# GD32E53x register map
File version: 1.0
CPU: CM33 r0p4, little endian, MPU, FPU, 4 interrupt priority bits
Registers are 32-bit, read-write, reset 0x0 unless marked. A register's access mark holds for its fields unless they carry their own. Offsets are from the block's base; [hi:lo] are bit positions; {n}, {i} and the like mark numbered series; 'fields as' and 'values as' point back to an identical list.

## SYSCFG — System and memory architectur
Base 0x40019800
0x00 CFG0 ro — Configuration register 0
  [2:0] BOOT_MODE
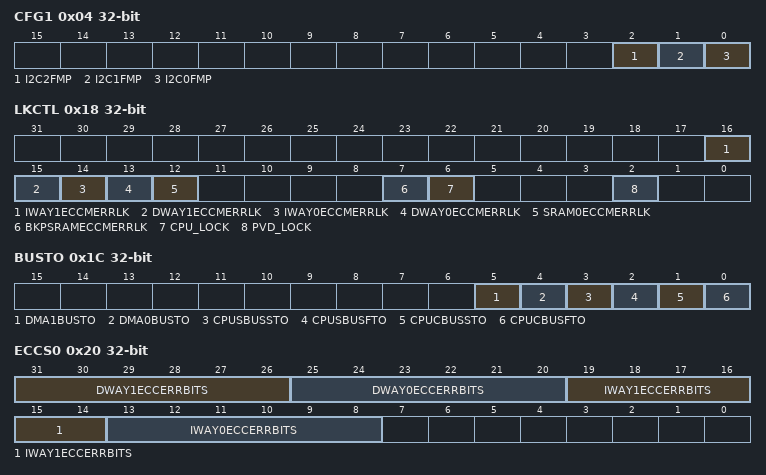
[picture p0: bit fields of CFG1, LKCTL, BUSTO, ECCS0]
0x04 CFG1 — Configuration register 1
  [2] I2C2FMP — I2C2 Fm+
  [1] I2C1FMP — I2C1 Fm+
  [0] I2C0FMP — I2C0 Fm+
0x18 LKCTL — Lockup control register
  [16] IWAY1ECCMERRLK — ICACHE way1 SRAM ECC multi-bits non-correction error lock bit
  [15] DWAY1ECCMERRLK — DCACHE way1 SRAM ECC multi-bits non-correction error lock bit
  [14] IWAY0ECCMERRLK — ICACHE way0 SRAM ECC multi-bits non-correction error lock bit
  [13] DWAY0ECCMERRLK — DCACHE way0 SRAM ECC multi-bits non-correction error lock bit
  [12] SRAM0ECCMERRLK — SRAM0 ECC multi-bits non-correction error lockup bit
  [7] BKPSRAMECCMERRLK — BKPSRAM ECC multi-bits non-correction lockup bit
  [6] CPU_LOCK — CPU lockup bit
  [2] PVD_LOCK — Programmable voltage detector lockup bit.
0x1C BUSTO — Bus timeout register
  [5] DMA1BUSTO — DMA1 bus timeout enable bit.
  [4] DMA0BUSTO — DMA0 bus timeout enable bit.
  [3] CPUSBUSSTO — CPU Sbus-Slow timeout enable bit.
  [2] CPUSBUSFTO — CPU Sbus-Fast timeout enable bit.
  [1] CPUCBUSSTO — CPU Cbus-Slow timeout enable bit.
  [0] CPUCBUSFTO — CPU Cbus-Fast timeout enable bit.
0x20 ECCS0 ro — SRAM_ECC error status register 0
  [31:26] DWAY1ECCERRBITS — Indicates the error bit of the DCACHE way1
  [25:20] DWAY0ECCERRBITS — Indicates the error bit of the DCACHE way0
  [19:14] IWAY1ECCERRBITS — Indicates the error bit of the ICACHE way1
  [13:8] IWAY0ECCERRBITS — Indicates the error bit of the ICACHE way0
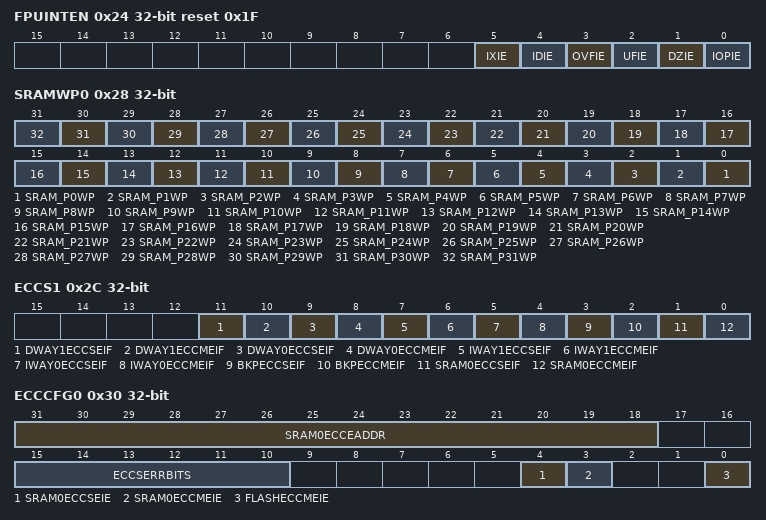
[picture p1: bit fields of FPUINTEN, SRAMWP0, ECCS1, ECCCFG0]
0x24 FPUINTEN reset 0x1F — FPU interrupt enable register
  [5] IXIE — Inexact interrupt enable bit
  [4] IDIE — Input denormal interrupt enable bit
  [3] OVFIE — Overflow interrupt enable bit
  [2] UFIE — Underflow interrupt enable bit
  [1] DZIE — Divide by 0 interrupt enable bit
  [0] IOPIE — Invalid operation interrupt enable bit
0x28 SRAMWP0 — SRAM write protection register0
  [n] SRAM_P{n}WP (n=0..31) — SRAM page {n} write protection
0x2C ECCS1 — SRAM ECC error status register 1
  [11] DWAY1ECCSEIF — DCACHE way1 SRAM single-bit correction event flag
  [10] DWAY1ECCMEIF — DCACHE way1 SRAM multi-bits non-correction error flag
  [9] DWAY0ECCSEIF — DCACHE way0 SRAM single-bit correction event flag
  [8] DWAY0ECCMEIF — DCACHE way0 SRAM multi-bits non-correction error flag
  [7] IWAY1ECCSEIF — ICACHE way1 SRAM single-bit correction event flag
  [6] IWAY1ECCMEIF — ICACHE way1 SRAM multi-bits non-correction error flag
  [5] IWAY0ECCSEIF — ICACHE way0 SRAM single-bit correction event flag
  [4] IWAY0ECCMEIF — ICACHE way0 SRAM multi-bits non-correction error flag
  [3] BKPECCSEIF — BKPSRAM single-bit correction event flag
  [2] BKPECCMEIF — BKPSRAM multi-bits non-correction error flag
  [1] SRAM0ECCSEIF — SRAM0 single bit correction error flag
  [0] SRAM0ECCMEIF — SRAM0 multi-bits non-correction error flag
0x30 ECCCFG0 access per field — ECC configuration register
  [31:18] SRAM0ECCEADDR ro — Record the faulting system address where the last SRAM ECC event on SRAM0 occurred.
  [15:10] ECCSERRBITS ro — Indicates the error bit
  [4] SRAM0ECCSEIE rw — SRAM0 single bit correction error NMI interrupt enable
  [3] SRAM0ECCMEIE rw — SRAM0 multi-bits non-correction error NMI interrupt enable
  [0] FLASHECCMEIE rw — Flash multi-bits non-correction error NMI interrupt enable
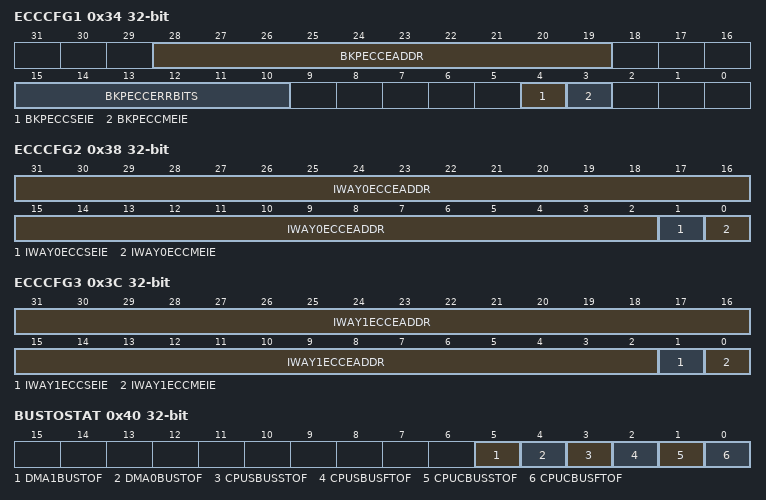
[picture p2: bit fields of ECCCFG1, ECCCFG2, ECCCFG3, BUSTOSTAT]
0x34 ECCCFG1 access per field — SRAM ECC configuration register
  [28:19] BKPECCEADDR ro — Indicates the last ECC event onBKPSRAM occurred.
  [15:10] BKPECCERRBITS ro — Indicates the error bit of the BKPSRAM
  [4] BKPECCSEIE rw — BKPSRAM single bit correction error interrupt enable
  [3] BKPECCMEIE rw — BKPSRAM multi-bits non-correction error NMI interrupt enable
0x38 ECCCFG2 access per field — SRAM ECC configuration register
  [31:2] IWAY0ECCEADDR ro — Indicates the last ECC event on ICACHE way0 SRAM occurred.
  [1] IWAY0ECCSEIE rw — ICACHE way0 single bit correction error interrupt enable
  [0] IWAY0ECCMEIE rw — ICACHE way0 multi-bits non-correction error NMI interrupt enable
0x3C ECCCFG3 access per field — SRAM ECC configuration register
  [31:2] IWAY1ECCEADDR ro — Indicates the last ECC event on ICACHE way1 SRAM occurred.
  [1] IWAY1ECCSEIE rw — ICACHE way1 single bit correction error NMI interrupt enable
  [0] IWAY1ECCMEIE rw — ICACHE way0 multi-bits (two bits) non-correction error NMI interrupt enable
0x40 BUSTOSTAT — Bus timeout states register
  [5] DMA1BUSTOF — DMA1 bus timeout flag.
  [4] DMA0BUSTOF — DMA0 bus timeout flag.
  [3] CPUSBUSSTOF — CPU Sbus-Slow timeout flag.
  [2] CPUSBUSFTOF — CPU Sbus-Fast timeout flag.
  [1] CPUCBUSSTOF — CPU Cbus-Slow timeout flag.
  [0] CPUCBUSFTOF — CPU Cbus-Fast timeout flag.
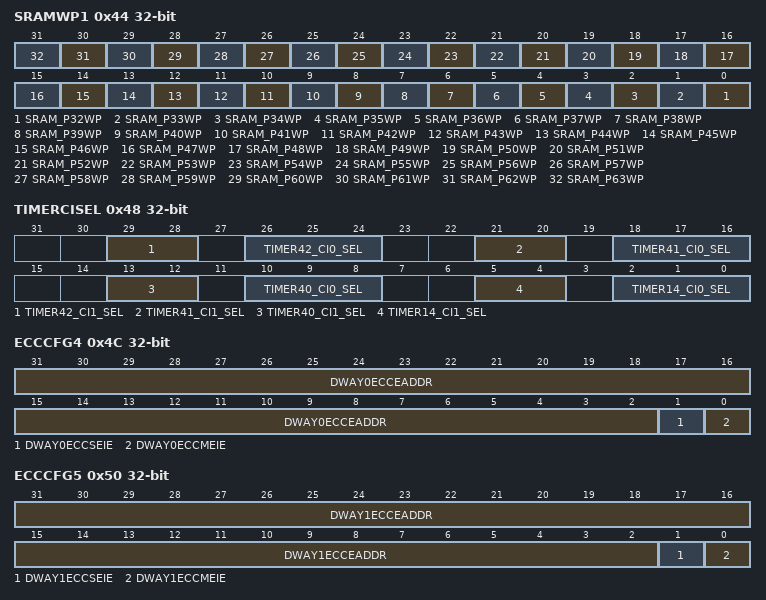
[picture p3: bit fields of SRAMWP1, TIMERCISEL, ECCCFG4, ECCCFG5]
0x44 SRAMWP1 — SRAM write protection register1
  [n-32] SRAM_P{n}WP (n=32..63) — SRAM page {n} write protection
0x48 TIMERCISEL — Timer input selection register
  [29:28] TIMER42_CI1_SEL — Selects TIMER42_CI1 input
  [26:24] TIMER42_CI0_SEL — Selects TIMER42_CI0 input
  [21:20] TIMER41_CI1_SEL — Selects TIMER41_CI1 input
  [18:16] TIMER41_CI0_SEL — Selects TIMER41_CI0 input
  [13:12] TIMER40_CI1_SEL — Selects TIMER40_CI1 input
  [10:8] TIMER40_CI0_SEL — Selects TIMER40_CI0 input
  [5:4] TIMER14_CI1_SEL — Selects TIMER14_CI1 input
  [2:0] TIMER14_CI0_SEL — Selects TIMER14_CI0 input
0x4C ECCCFG4 access per field — SRAM ECC configuration register
  [31:2] DWAY0ECCEADDR ro — Indicates the last ECC event on DCACHE way0 SRAM occurred.
  [1] DWAY0ECCSEIE rw — DCHACHE way0 single bit correction error NMI interrupt enable
  [0] DWAY0ECCMEIE rw — DCHACHE way0 multi-bits non-correction error NMI interrupt enable
0x50 ECCCFG5 access per field — SRAM ECC configuration register5
  [31:2] DWAY1ECCEADDR ro — Indicates the last ECC event on DCACHE way1 SRAM occurred.
  [1] DWAY1ECCSEIE rw — DCHACHE way1 single bit correction error NMI interrupt enable
  [0] DWAY1ECCMEIE rw — DCHACHE way1 multi-bits (two bits) non-correction error NMI interrupt enable
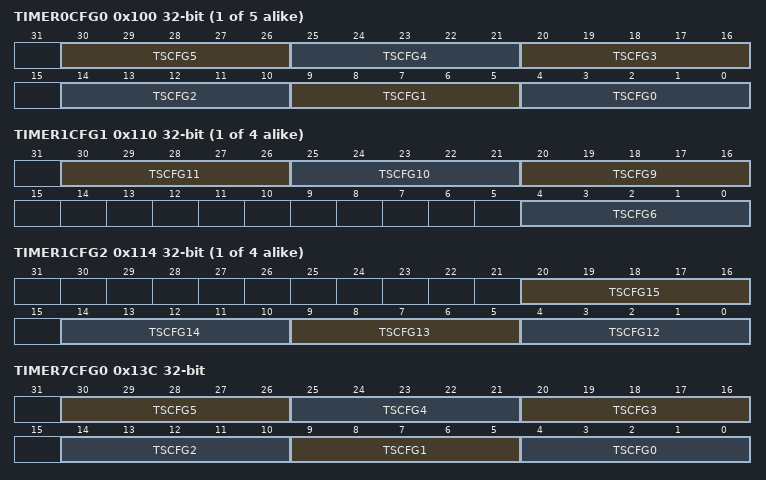
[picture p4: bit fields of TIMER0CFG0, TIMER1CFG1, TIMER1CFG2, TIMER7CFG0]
{0x100+0xC*i} TIMER{i}CFG0 (i=0..4) — TIMER{i} configuration register 0
  [30:26] TSCFG5 — Event mode configuration
  [25:21] TSCFG4 — Pause mode configuration
  [20:16] TSCFG3 — Restart mode configuration
  [14:10] TSCFG2 — Quadrature decoder mode 2 configuration
  [9:5] TSCFG1 — Quadrature decoder mode 1 configuration
  [4:0] TSCFG0 — Quadrature decoder mode 0 configuration
0x104 TIMER0CFG1 — TIMER0 configuration register 1
  [4:0] TSCFG6 — External clock mode 0 configuration
0x108 TIMER0CFG2 — TIMER0 configuration register 2
  [20:16] TSCFG15 — Internal trigger input source configuration
{0x104+0xC*i} TIMER{i}CFG1 (i=1..4) — TIMER{i} configuration register 1
  [30:26] TSCFG11 — Decoder mode 2 configuration
  [25:21] TSCFG10 — Decoder mode 1 configuration
  [20:16] TSCFG9 — Decoder mode 0 configuration
  [4:0] TSCFG6 — External clock mode 0 configuration
{0x108+0xC*i} TIMER{i}CFG2 (i=1..4) — TIMER{i} configuration register 2
  [20:16] TSCFG15 — Internal trigger input source configuration
  [14:10] TSCFG14 — Quadrature decoder mode 4 configuration
  [9:5] TSCFG13 — Quadrature decoder mode 3 configuration
  [4:0] TSCFG12 — Decoder mode 3 configuration
0x13C TIMER7CFG0 — TIMER7 configuration register 0
  fields as TIMER0CFG0
0x140 TIMER7CFG1 — TIMER7 configuration register 1
  [4:0] TSCFG6 — External clock mode 0 configuration
0x144 TIMER7CFG2 — TIMER7 configuration register 2
  [20:16] TSCFG15 — Internal trigger input source configuration
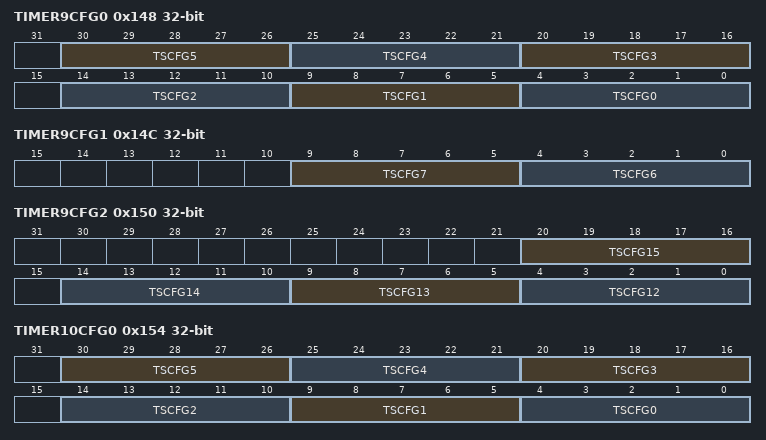
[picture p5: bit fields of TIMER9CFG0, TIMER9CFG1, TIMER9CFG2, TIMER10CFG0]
0x148 TIMER9CFG0 — TIMER9 configuration register 0
  [30:26] TSCFG5 — Event mode configuration
  [25:21] TSCFG4 — Pause mode configuration
  [20:16] TSCFG3 — Restart mode configuration
  [14:10] TSCFG2 — Decoder mode 2 configuration
  [9:5] TSCFG1 — Decoder mode 1 configuration
  [4:0] TSCFG0 — Decoder mode 0 configuration
0x14C TIMER9CFG1 — TIMER9 configuration register 1
  [9:5] TSCFG7 — Restart and event mode configuration
  [4:0] TSCFG6 — External clock mode 0 configuration
0x150 TIMER9CFG2 — TIMER9 configuration register 2
  [20:16] TSCFG15 — Internal trigger input source configuration
  [14:10] TSCFG14 — 500000: Disable
  [9:5] TSCFG13 — 500000: Disable
  [4:0] TSCFG12 — 500000: Disable
0x154 TIMER10CFG0 — TIMER10 configuration register 0
  fields as TIMER9CFG0
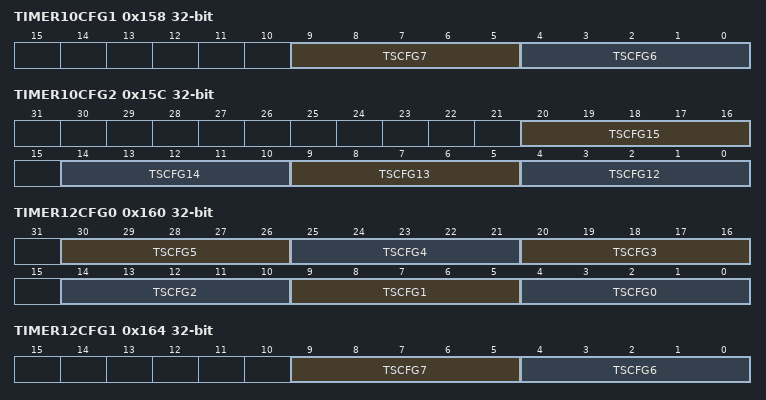
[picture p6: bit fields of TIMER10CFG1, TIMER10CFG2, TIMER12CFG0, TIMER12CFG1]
0x158 TIMER10CFG1 — TIMER10 configuration register 1
  fields as TIMER9CFG1
0x15C TIMER10CFG2 — TIMER10 configuration register 2
  fields as TIMER9CFG2
0x160 TIMER12CFG0 — TIMER12 configuration register 0
  fields as TIMER9CFG0
0x164 TIMER12CFG1 — TIMER12 configuration register 1
  fields as TIMER9CFG1
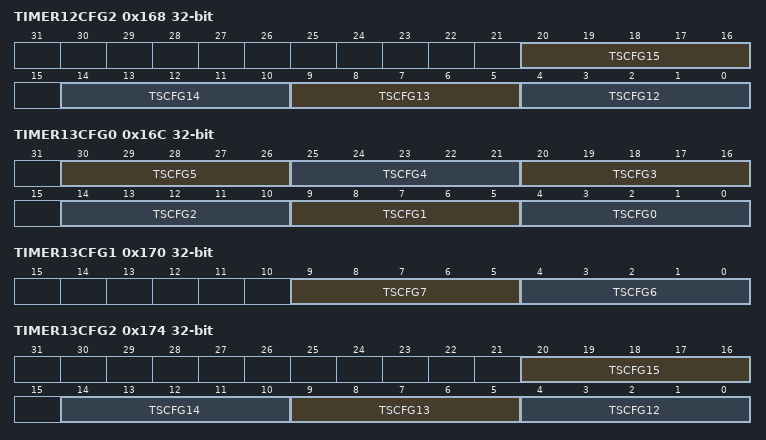
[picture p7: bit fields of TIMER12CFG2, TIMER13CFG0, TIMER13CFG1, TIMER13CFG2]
0x168 TIMER12CFG2 — TIMER12 configuration register 2
  fields as TIMER9CFG2
0x16C TIMER13CFG0 — TIMER13 configuration register 0
  fields as TIMER9CFG0
0x170 TIMER13CFG1 — TIMER13 configuration register 1
  fields as TIMER9CFG1
0x174 TIMER13CFG2 — TIMER13 configuration register 2
  fields as TIMER9CFG2
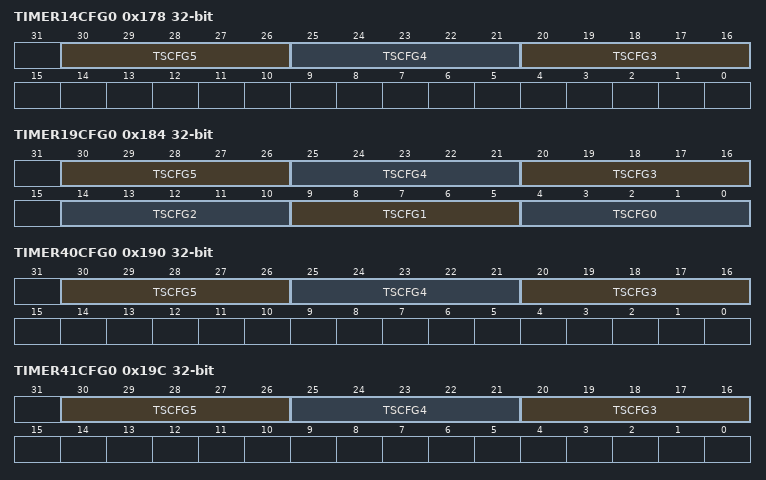
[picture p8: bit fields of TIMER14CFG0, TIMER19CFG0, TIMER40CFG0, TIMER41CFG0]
0x178 TIMER14CFG0 — TIMER14 configuration register 0
  [30:26] TSCFG5 — Event mode configuration
  [25:21] TSCFG4 — Pause mode configuration
  [20:16] TSCFG3 — Restart mode configuration
0x17C TIMER14CFG1 — TIMER14 configuration register 1
  [4:0] TSCFG6 — External clock mode 0 configuration
0x180 TIMER14CFG2 — TIMER14 configuration register 2
  [20:16] TSCFG15 — Internal trigger input source configuration
0x184 TIMER19CFG0 — TIMER19 configuration register 0
  fields as TIMER0CFG0
0x188 TIMER19CFG1 — TIMER19 configuration register 1
  [4:0] TSCFG6 — External clock mode 0 configuration
0x18C TIMER19CFG2 — TIMER19 configuration register 2
  [20:16] TSCFG15 — Internal trigger input source configuration
0x190 TIMER40CFG0 — TIMER40 configuration register 0
  fields as TIMER14CFG0
0x194 TIMER40CFG1 — TIMER40 configuration register 1
  [4:0] TSCFG6 — External clock mode 0 configuration
0x198 TIMER40CFG2 — TIMER40 configuration register 2
  [20:16] TSCFG15 — Internal trigger input source configuration
0x19C TIMER41CFG0 — TIMER41 configuration register 0
  fields as TIMER14CFG0
0x1A0 TIMER41CFG1 — TIMER41 configuration register 1
  [4:0] TSCFG6 — External clock mode 0 configuration
0x1A4 TIMER41CFG2 — TIMER41 configuration register 2
  [20:16] TSCFG15 — Internal trigger input source configuration
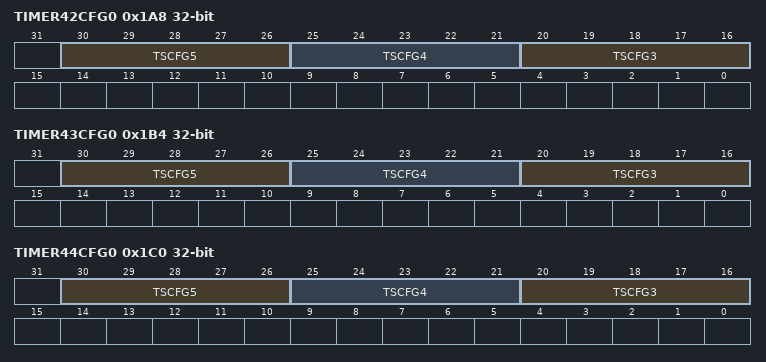
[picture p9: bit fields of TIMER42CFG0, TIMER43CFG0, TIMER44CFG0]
0x1A8 TIMER42CFG0 — TIMER42 configuration register 0
  fields as TIMER14CFG0
0x1AC TIMER42CFG1 — TIMER42 configuration register 1
  [4:0] TSCFG6 — External clock mode 0 configuration
0x1B0 TIMER42CFG2 — TIMER42 configuration register 2
  [20:16] TSCFG15 — Internal trigger input source configuration
0x1B4 TIMER43CFG0 — TIMER43 configuration register 0
  fields as TIMER14CFG0
0x1B8 TIMER43CFG1 — TIMER43 configuration register 1
  [4:0] TSCFG6 — External clock mode 0 configuration
0x1BC TIMER43CFG2 — TIMER43 configuration register 2
  [20:16] TSCFG15 — Internal trigger input source configuration
0x1C0 TIMER44CFG0 — TIMER44 configuration register 0
  fields as TIMER14CFG0
0x1C4 TIMER44CFG1 — TIMER44 configuration register 1
  [4:0] TSCFG6 — External clock mode 0 configuration
0x1C8 TIMER44CFG2 — TIMER44 configuration register 2
  [20:16] TSCFG15 — Internal trigger input source configuration
